# M05x_registers register map
File version: 0.1
CPU: 
Registers are 32-bit, read-write, reset 0x0 unless marked. A register's access mark holds for its fields unless they carry their own. Offsets are from the block's base; [hi:lo] are bit positions; lines under a group give offsets from that group; {n}, {i} and the like mark numbered series.

## GPIO — Registers group
Base 0x50004180
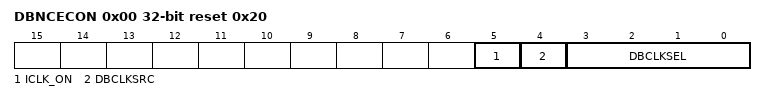
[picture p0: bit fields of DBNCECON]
0x00 DBNCECON reset 0x20 (reset mask 0xFFFFFFDF) — Interrupt De-bounce Cycle Control
  [5] ICLK_ON — Interrupt clock On mode Set this bit "0" will disable the interrupt generate circuit clock, if the pin[n] interrupt is disabled 0 = disable the clock if the P0/1/2/3/4[n] interrupt is disabled 1 = interrupt generated circuit clock always enable n=0~7
  [4] DBCLKSRC — De-bounce counter clock source select 1 = De-bounce counter clock source is the internal 10KHz clock 0 = De-bounce counter clock source is the HCLK
  [3:0] DBCLKSEL — De-bounce sampling cycle selection DBCLKSEL Description 0 Sample interrupt input once per 1 clocks 1 Sample interrupt input once per 2 clocks 2 Sample interrupt input once per 4 clocks 3 Sample interrupt input once per 8 clocks 4 Sample interrupt input once per 16 clocks 5 Sample interrupt input once per 32 clocks 6 Sample interrupt input once per 64 clocks 7 Sample interrupt input once per 128 clocks 8 Sample interrupt input once per 256 clocks 9 Sample interrupt input once per 2*256 clocks 10 Sample interrupt input once per 4*256clocks 11 Sample interrupt input once per 8*256 clocks 12 Sample interrupt input once per 16*256 clocks 13 Sample interrupt input once per 32*256 clocks 14 Sample interrupt input once per 64*256 clocks 15 Sample interrupt input once per 128*256 clocks

## GP0_BITS — Registers group
Base 0x50004200
Same registers: GP1_BITS 0x50004220, GP2_BITS 0x50004240, GP3_BITS 0x50004260, GP4_BITS 0x50004280
0x200 Px0_DOUT reset 0x1 (reset mask 0xFFFFFFFE) — Px.0 Data Output Value
  [0] DOUT — P0.0 I/O Pin Bit Output Control Set this bit can control one GPIO pin output value 1 = Set corresponding GPIO bit to high 0 = Set corresponding GPIO bit to low
0x204 Px1_DOUT reset 0x1 (reset mask 0xFFFFFFFE) — Px.1 Data Output Value
  [0] DOUT — P0.1 I/O Pin Bit Output Control Set this bit can control one GPIO pin output value 1 = Set corresponding GPIO bit to high 0 = Set corresponding GPIO bit to low
0x208 Px2_DOUT reset 0x1 (reset mask 0xFFFFFFFE) — Px.2 Data Output Value
  [0] DOUT — P0.2 I/O Pin Bit Output Control Set this bit can control one GPIO pin output value 1 = Set corresponding GPIO bit to high 0 = Set corresponding GPIO bit to low
0x20C Px3_DOUT reset 0x1 (reset mask 0xFFFFFFFE) — Px.3 Data Output Value
  [0] DOUT — P0.3 I/O Pin Bit Output Control Set this bit can control one GPIO pin output value 1 = Set corresponding GPIO bit to high 0 = Set corresponding GPIO bit to low
0x210 Px4_DOUT reset 0x1 (reset mask 0xFFFFFFFE) — Px.4 Data Output Value
  [0] DOUT — P0.4 I/O Pin Bit Output Control Set this bit can control one GPIO pin output value 1 = Set corresponding GPIO bit to high 0 = Set corresponding GPIO bit to low
0x214 Px5_DOUT reset 0x1 (reset mask 0xFFFFFFFE) — Px.5 Data Output Value
  [0] DOUT — P0.5 I/O Pin Bit Output Control Set this bit can control one GPIO pin output value 1 = Set corresponding GPIO bit to high 0 = Set corresponding GPIO bit to low
0x218 Px6_DOUT reset 0x1 (reset mask 0xFFFFFFFE) — Px.6 Data Output Value
  [0] DOUT — P0.6 I/O Pin Bit Output Control Set this bit can control one GPIO pin output value 1 = Set corresponding GPIO bit to high 0 = Set corresponding GPIO bit to low
0x21C Px7_DOUT reset 0x1 (reset mask 0xFFFFFFFE) — Px.7 Data Output Value
  [0] DOUT — P0.7 I/O Pin Bit Output Control Set this bit can control one GPIO pin output value 1 = Set corresponding GPIO bit to high 0 = Set corresponding GPIO bit to low

## INT — Registers group
Base 0x50000300
0x00 IRQ0_SRC ro reset not defined — MCU IRQ0 (BOD) interrupt source identify
  [2:0] INT_SRC — Bit2 = 0 Bit1 = 0 Bit0: BOD_INT
0x04 IRQ1_SRC ro reset not defined — MCU IRQ1 (WDT) interrupt source identify
  [2:0] INT_SRC — Bit2 = 0 Bit1 = 0 Bit0: WDT_INT
0x08 IRQ2_SRC ro reset not defined — MCU IRQ2 ((EINT0) interrupt source identify
  [2:0] INT_SRC — Bit2 = 0 Bit1 = 0 Bit0: EINT0 - external interrupt 0 from P3.2
0x0C IRQ3_SRC ro reset not defined — MCU IRQ3 (EINT1) interrupt source identify
  [2:0] INT_SRC — Bit2 = 0 Bit1 = 0 Bit0: EINT1 - external interrupt 1 from P3.3
0x10 IRQ4_SRC ro reset not defined — MCU IRQ4 (P0/1) interrupt source identify
  [2:0] INT_SRC — Bit2 = 0 Bit1: P1_INT Bit0: P0_INT
0x14 IRQ5_SRC ro reset not defined — MCU IRQ5 (P2/3/4) interrupt source identify
  [2:0] INT_SRC — Bit2: P4_INT Bit1: P3_INT Bit0: P2_INT
0x18 IRQ6_SRC ro reset not defined — MCU IRQ6 (PWMA) interrupt source identify
  [3:0] INT_SRC — Bit3: PWM3_INT Bit2: PWM2_INT Bit1: PWM1_INT Bit0: PWM0_INT
0x1C IRQ7_SRC ro reset not defined — MCU IRQ7 (PWMB) interrupt source identify
  [3:0] INT_SRC — Bit3: PWM7_INT Bit2: PWM6_INT Bit1: PWM5_INT Bit0: PWM4_INT
{0x0+4i} IRQ{i}_SRC ro reset not defined (i=8..11) — MCU IRQ{i} (TMR{i-8}) interrupt source identify
  [2:0] INT_SRC — Bit2 = 0 Bit1 = 0 Bit0: TMR{i-8}_INT
0x30 IRQ12_SRC ro reset not defined — MCU IRQ12 (URT0) interrupt source identify
  [2:0] INT_SRC — Bit2 = 0 Bit1 = 0 Bit0: URT0_INT
0x34 IRQ13_SRC ro reset not defined — MCU IRQ13 (URT1) interrupt source identify
  [2:0] INT_SRC — Bit2 = 0 Bit1 = 0 Bit0: URT1_INT
0x38 IRQ14_SRC ro reset not defined — MCU IRQ14 (SPI0) interrupt source identify
  [2:0] INT_SRC — Bit2 = 0 Bit1 = 0 Bit0: SPI0_INT
0x3C IRQ15_SRC ro reset not defined — MCU IRQ15 (SPI1) interrupt source identify
  [2:0] INT_SRC — Bit2 = 0 Bit1 = 0 Bit0: SPI1_INT
0x48 IRQ18_SRC ro reset not defined — MCU IRQ18 (I2C) interrupt source identify
  [2:0] INT_SRC — Bit2 = 0 Bit1 = 0 Bit0: I2C_INT
0x54 IRQ21_SRC ro reset not defined — MCU IRQ21 (Reserved) interrupt source identify
  [2:0] INT_SRC — Reserved
0x58 IRQ22_SRC ro reset not defined — MCU IRQ22 (Reserved) interrupt source identify
  [2:0] INT_SRC — Reserved
0x70 IRQ28_SRC ro reset not defined — MCU IRQ28 (PWRWU) interrupt source identify
  [2:0] INT_SRC — Bit2 = 0 Bit1 = 0 Bit0: PWRWU_INT
0x74 IRQ29_SRC ro reset not defined — MCU IRQ29 (ADC) interrupt source identify
  [2:0] INT_SRC — Bit2 = 0 Bit1 = 0 Bit0: ADC_INT
0x78 IRQ30_SRC ro reset not defined — MCU IRQ30 (Reserved) interrupt source identify
  [2:0] INT_SRC — Reserved
0x80 NMI_SEL — NMI source interrupt select control register
  [4:0] NMI_SEL — The NMI interrupt to Cortex-M0 can be selected from one of the interrupt[31:0] The NMI_SEL bit[4:0] used to select the NMI interrupt source
0x84 MCU_IRQ — MCU IRQ Number identify register
  [31:0] MCU_IRQ write-1-clears — MCU IRQ Source Register The MCU_IRQ collect all the interrupts from the peripherals and generate the synchronous interrupt to MCU Cortex-M0. There are two modes to generate interrupt to MCU Cortex-M0, the normal mode and test mode. The MCU_IRQ collects all interrupts from each peripheral and synchronizes them then interrupts the Cortex-M0. When the MCU_IRQ[n] is "0": Set MCU_IRQ[n] "1" will generate an interrupt to Cortex_M0 NVIC[n]. When the MCU_IRQ[n] is "1"(mean an interrupt is assert) set 1 the MCU_bit[n] will clear the interrupt Set MCU_IRQ[n] "0": no any effect
